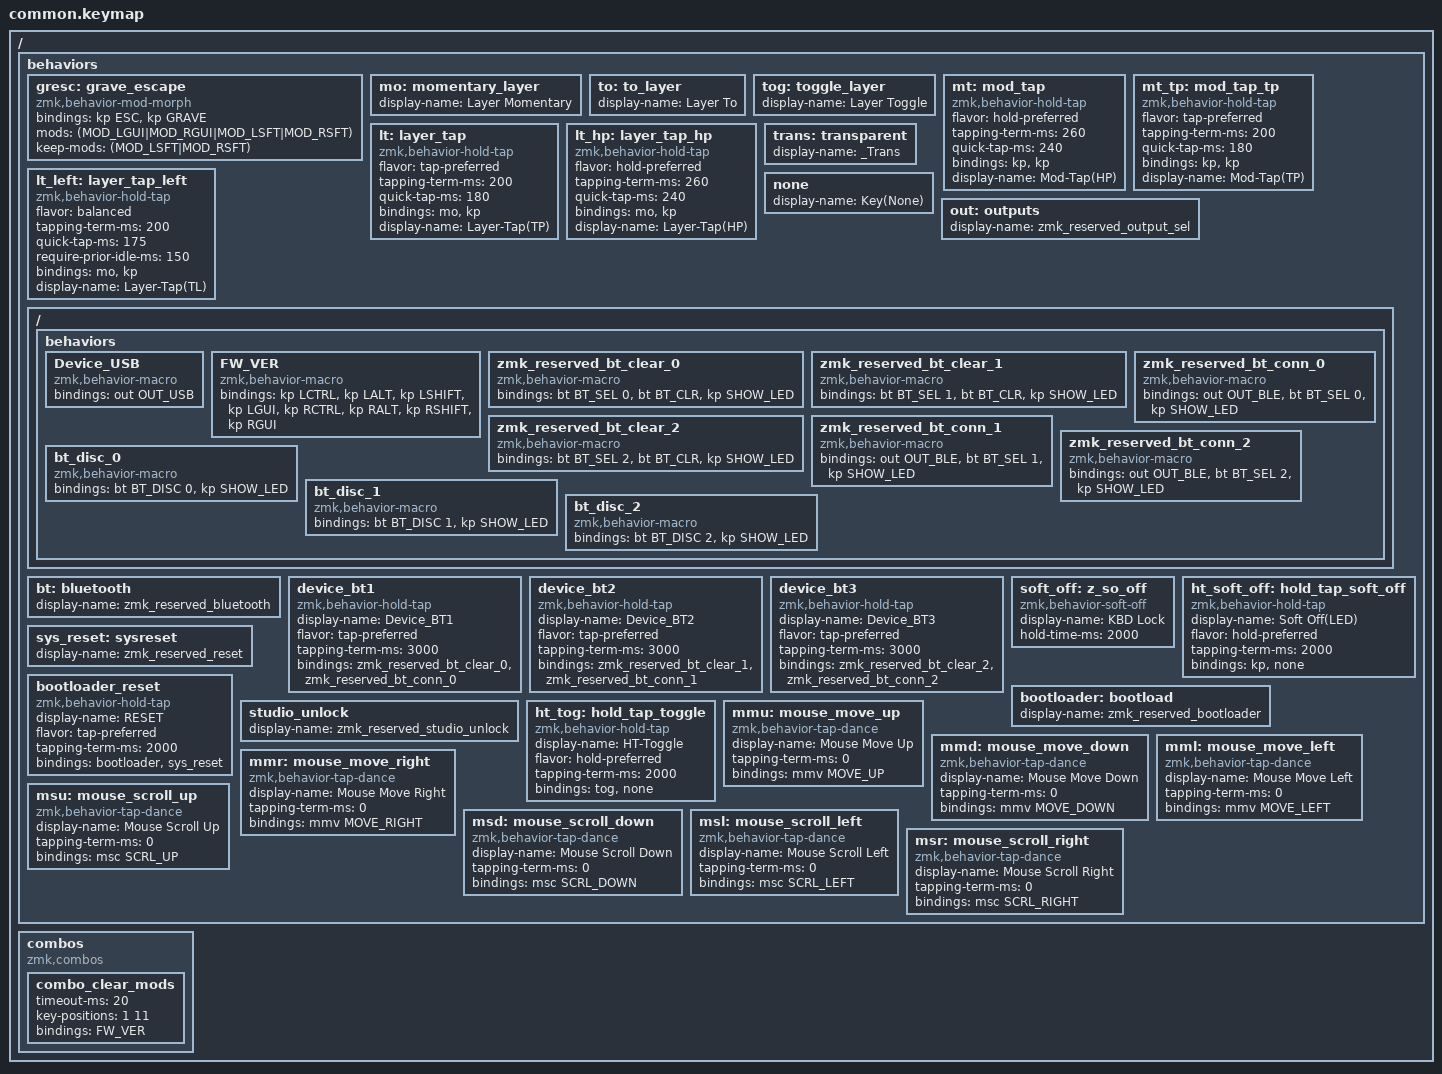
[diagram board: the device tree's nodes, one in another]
/*
 * Copyright (c) 2021 The ZMK Contributors
 *
 * SPDX-License-Identifier: MIT
 */
/*
 * Firmware version macro identifier
 * Note: Named for ZMK Studio's reserved behavior naming convention.
 * Actual output: modifier key combination as version indicator.
 */
#define FW_VER zmk_firmware_version_251115

/* ========================================
 * Section 1: Behavior Omission Definitions
 * ======================================== */
#define ZMK_BEHAVIORS_OMIT_CAPS_WORD        // &caps_word
#define ZMK_BEHAVIORS_OMIT_KT               // &kt, Key Toggle
#define ZMK_BEHAVIORS_OMIT_KEY_REPEAT       // &key_repeat, Key Repeat
#define ZMK_BEHAVIORS_OMIT_SK               // &sk, Sticky Key
#define ZMK_BEHAVIORS_OMIT_STICKY_LAYER     // &sl, Sticky Layer

#include <behaviors.dtsi>
#include <dt-bindings/zmk/keys.h>
#include <dt-bindings/zmk/pointing.h>
#include <dt-bindings/zmk/bt.h>
#include <dt-bindings/zmk/outputs.h>

/ {
    behaviors {
        /* ========================================
         * Section 2: Core Behaviors (gresc, mt, lt)
         * ======================================== */
        gresc: grave_escape {
            compatible = "zmk,behavior-mod-morph";
            #binding-cells = <0>;
            bindings = <&kp ESC>, <&kp GRAVE>;
            mods = <(MOD_LGUI|MOD_RGUI|MOD_LSFT|MOD_RSFT)>;
            keep-mods = <(MOD_LSFT|MOD_RSFT)>;
        };

        mo: momentary_layer { display-name = "Layer Momentary"; };
        to: to_layer { display-name = "Layer To"; };
        tog: toggle_layer { display-name = "Layer Toggle"; };

        // mt default: hold preferred. Rename it.
        mt: mod_tap {
            compatible = "zmk,behavior-hold-tap";
            #binding-cells = <2>;
            flavor = "hold-preferred";
            tapping-term-ms = <260>;
            quick-tap-ms = <240>;
            bindings = <&kp>, <&kp>;
            display-name = "Mod-Tap(HP)";
        };

        // mt_tp tap preferred
        mt_tp: mod_tap_tp {
            compatible = "zmk,behavior-hold-tap";
            #binding-cells = <2>;
            flavor = "tap-preferred";
            tapping-term-ms = <200>;
            quick-tap-ms = <180>;
            bindings = <&kp>, <&kp>;
            display-name = "Mod-Tap(TP)";
        };

        // lt default: tap preferred. Rename it.
        lt: layer_tap {
            compatible = "zmk,behavior-hold-tap";
            #binding-cells = <2>;
            flavor = "tap-preferred";
            tapping-term-ms = <200>;
            quick-tap-ms = <180>;
            bindings = <&mo>, <&kp>;
            display-name = "Layer-Tap(TP)";
        };

        // lt_hp:  hold preferred
        lt_hp: layer_tap_hp {
            compatible = "zmk,behavior-hold-tap";
            #binding-cells = <2>;
            flavor = "hold-preferred";
            tapping-term-ms = <260>;
            quick-tap-ms = <240>;
            bindings = <&mo>, <&kp>;
            display-name = "Layer-Tap(HP)";
        };

        // lt_left: timeless layer-tap for left space
        lt_left: layer_tap_left {
            compatible = "zmk,behavior-hold-tap";
            #binding-cells = <2>;
            flavor = "balanced";
            tapping-term-ms = <200>;
            quick-tap-ms = <175>;
            require-prior-idle-ms = <150>;
            bindings = <&mo>, <&kp>;
            display-name = "Layer-Tap(TL)";
        };

        // Rename trans and none for ZMK Studio display; trans listed first
        trans: transparent { display-name = "_Trans"; };
        none: none { display-name = "Key(None)"; };

        /* ========================================
         * Section 3: Device Control (USB, BT, Reset)
         * ======================================== */
        out: outputs { display-name = "zmk_reserved_output_sel"; };
        ZMK_MACRO(Device_USB, bindings = <&out OUT_USB>;)

        bt: bluetooth { display-name = "zmk_reserved_bluetooth"; };

        #define SHOW_LED 0xAB      // Show BLE connection status
        #define SHOW_BATTERY 0xAC  // Show battery level
        #define SHOW_SOFT_OFF 0xAD // Soft off with LED feedback
        ZMK_MACRO(FW_VER, bindings = <&kp LCTRL &kp LALT &kp LSHIFT &kp LGUI &kp RCTRL &kp RALT &kp RSHIFT &kp RGUI>;)
        ZMK_MACRO(zmk_reserved_bt_clear_0, bindings = <&bt BT_SEL 0>, <&bt BT_CLR>, <&kp SHOW_LED>;)
        ZMK_MACRO(zmk_reserved_bt_clear_1, bindings = <&bt BT_SEL 1>, <&bt BT_CLR>, <&kp SHOW_LED>;)
        ZMK_MACRO(zmk_reserved_bt_clear_2, bindings = <&bt BT_SEL 2>, <&bt BT_CLR>, <&kp SHOW_LED>;)

        ZMK_MACRO(zmk_reserved_bt_conn_0,  bindings = <&out OUT_BLE>, <&bt BT_SEL 0>, <&kp SHOW_LED>;)
        ZMK_MACRO(zmk_reserved_bt_conn_1,  bindings = <&out OUT_BLE>, <&bt BT_SEL 1>, <&kp SHOW_LED>;)
        ZMK_MACRO(zmk_reserved_bt_conn_2,  bindings = <&out OUT_BLE>, <&bt BT_SEL 2>, <&kp SHOW_LED>;)

        ZMK_MACRO(bt_disc_0,  bindings = <&bt BT_DISC 0>, <&kp SHOW_LED>;)
        ZMK_MACRO(bt_disc_1,  bindings = <&bt BT_DISC 1>, <&kp SHOW_LED>;)
        ZMK_MACRO(bt_disc_2,  bindings = <&bt BT_DISC 2>, <&kp SHOW_LED>;)

        device_bt1: device_bt1 {
            compatible = "zmk,behavior-hold-tap";
            display-name = "Device_BT1";
            #binding-cells = <2>;
            flavor = "tap-preferred";
            tapping-term-ms = <3000>;  // delay amount in ms
            bindings = <&zmk_reserved_bt_clear_0>, <&zmk_reserved_bt_conn_0>;
        };
        device_bt2: device_bt2 {
            compatible = "zmk,behavior-hold-tap";
            display-name = "Device_BT2";
            #binding-cells = <2>;
            flavor = "tap-preferred";
            tapping-term-ms = <3000>;  // delay amount in ms
            bindings = <&zmk_reserved_bt_clear_1>, <&zmk_reserved_bt_conn_1>;
        };
        device_bt3: device_bt3 {
            compatible = "zmk,behavior-hold-tap";
            display-name = "Device_BT3";
            #binding-cells = <2>;
            flavor = "tap-preferred";
            tapping-term-ms = <3000>;  // delay amount in ms
            bindings = <&zmk_reserved_bt_clear_2>, <&zmk_reserved_bt_conn_2>;
        };
        //
        soft_off: z_so_off {
            compatible = "zmk,behavior-soft-off";
            display-name = "KBD Lock";
            #binding-cells = <0>;
            hold-time-ms = <2000>;
        };

        /*
         * Soft off with LED feedback
         * Hold (2s): Red LED blink -> soft_off
         * Tap: None
         */
        ht_soft_off: hold_tap_soft_off {
            compatible = "zmk,behavior-hold-tap";
            display-name = "Soft Off(LED)";
            #binding-cells = <2>;
            flavor = "hold-preferred";
            tapping-term-ms = <2000>;
            bindings = <&kp>, <&none>;
        };

        sys_reset: sysreset { display-name = "zmk_reserved_reset"; };
        bootloader: bootload { display-name = "zmk_reserved_bootloader"; };

        bootloader_reset: bootloader_reset {
            compatible = "zmk,behavior-hold-tap";
            display-name = "RESET";
            #binding-cells = <2>;
            flavor = "tap-preferred";
            tapping-term-ms = <2000>;  // delay amount in ms
            bindings = <&bootloader>, <&sys_reset>;
        };

        studio_unlock: studio_unlock { display-name = "zmk_reserved_studio_unlock"; };

        /*
         * Hold-tap for layer toggle
         * Usage: &ht_tog LAYER 0
         * Hold (2s): Toggle layer on/off
         * Tap: None (no action)
         */
        ht_tog: hold_tap_toggle {
            compatible = "zmk,behavior-hold-tap";
            display-name = "HT-Toggle";
            #binding-cells = <2>;
            flavor = "hold-preferred";
            tapping-term-ms = <2000>;
            bindings = <&tog>, <&none>;
        };

        /* ========================================
         * Section 4: Mouse Behaviors
         * Note: tapping-term-ms = 0 means these function as simple key bindings.
         * This is intentional for ZMK Studio display purposes.
         * To enable tap-dance, set tapping-term-ms > 0 and add bindings.
         * ======================================== */
        mmu:mouse_move_up {
            compatible = "zmk,behavior-tap-dance";
            display-name = "Mouse Move Up";
            #binding-cells = <0>;
            tapping-term-ms = <0>;
            bindings = <&mmv MOVE_UP>;
        };
        mmd:mouse_move_down {
            compatible = "zmk,behavior-tap-dance";
            display-name = "Mouse Move Down";
            #binding-cells = <0>;
            tapping-term-ms = <0>;
            bindings = <&mmv MOVE_DOWN>;
        };
        mml:mouse_move_left {
            compatible = "zmk,behavior-tap-dance";
            display-name = "Mouse Move Left";
            #binding-cells = <0>;
            tapping-term-ms = <0>;
            bindings = <&mmv MOVE_LEFT>;
        };
        mmr:mouse_move_right {
            compatible = "zmk,behavior-tap-dance";
            display-name = "Mouse Move Right";
            #binding-cells = <0>;
            tapping-term-ms = <0>;
            bindings = <&mmv MOVE_RIGHT>;
        };
        //mouse scroll
        msu:mouse_scroll_up {
            compatible = "zmk,behavior-tap-dance";
            display-name = "Mouse Scroll Up";
            #binding-cells = <0>;
            tapping-term-ms = <0>;
            bindings = <&msc SCRL_UP>;
        };
        msd:mouse_scroll_down {
            compatible = "zmk,behavior-tap-dance";
            display-name = "Mouse Scroll Down";
            #binding-cells = <0>;
            tapping-term-ms = <0>;
            bindings = <&msc SCRL_DOWN>;
        };
        msl:mouse_scroll_left {
            compatible = "zmk,behavior-tap-dance";
            display-name = "Mouse Scroll Left";
            #binding-cells = <0>;
            tapping-term-ms = <0>;
            bindings = <&msc SCRL_LEFT>;
        };
        msr:mouse_scroll_right {
            compatible = "zmk,behavior-tap-dance";
            display-name = "Mouse Scroll Right";
            #binding-cells = <0>;
            tapping-term-ms = <0>;
            bindings = <&msc SCRL_RIGHT>;
        };
    };
    combos {
        compatible = "zmk,combos";
        combo_clear_mods {
            timeout-ms = <20>;
            key-positions = <1 11>; // Q  and \|
            bindings = <&FW_VER>;
        };
    };
};
